AUTOSAR XML (schema 4-2-2)
package /ComponentTypes
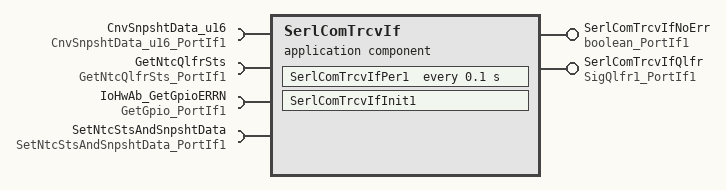
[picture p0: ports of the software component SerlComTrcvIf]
  application sw component type SerlComTrcvIf
    provide port SerlComTrcvIfNoErr: nonqueued-sender-com-spec{data-element=Logl, init-value=0}, provided-interface=boolean_PortIf1
    provide port SerlComTrcvIfQlfr: nonqueued-sender-com-spec{data-element=Val, init-value=0}, provided-interface=SigQlfr1_PortIf1
    4 x require port, all with client-com-spec=Oper:
      CnvSnpshtData_u16: required-interface=CnvSnpshtData_u16_PortIf1
      GetNtcQlfrSts: required-interface=GetNtcQlfrSts_PortIf1
      IoHwAb_GetGpioERRN: required-interface=GetGpio_PortIf1
      SetNtcStsAndSnpshtData: required-interface=SetNtcStsAndSnpshtData_PortIf1
    behavior SerlComTrcvIf_InternalBehavior
      ar-typed-per-instance-memorys:
        4 x data, all with sw-calibration-access=READ-ONLY:
          dSerlComTrcvIfStsReg: type=uint16
          SerlComTrcvIfFltErrPin: type=boolean
          SerlComTrcvIfSpiErrCntr: type=uint8
          SerlComTrcvIfSt: type=uint8
      init event SerlComTrcvIf_InitEvent: start-on-event=SerlComTrcvIfInit1
      timing event TMT_SerlComTrcvIfPer1: start-on-event=SerlComTrcvIfPer1, period=0.1
      port-api-options:
        enable-take-address=false, error-handling=NO-TRANSFORMER-ERROR-HANDLING, indirect-api=false, port=CnvSnpshtData_u16
        enable-take-address=false, error-handling=NO-TRANSFORMER-ERROR-HANDLING, indirect-api=false, port=GetNtcQlfrSts
        enable-take-address=false, error-handling=NO-TRANSFORMER-ERROR-HANDLING, indirect-api=false, port=IoHwAb_GetGpioERRN
        enable-take-address=false, error-handling=NO-TRANSFORMER-ERROR-HANDLING, indirect-api=false, port=SerlComTrcvIfNoErr
        enable-take-address=false, error-handling=NO-TRANSFORMER-ERROR-HANDLING, indirect-api=false, port=SerlComTrcvIfQlfr
        enable-take-address=false, error-handling=NO-TRANSFORMER-ERROR-HANDLING, indirect-api=false, port=SetNtcStsAndSnpshtData
      runnable SerlComTrcvIfInit1
      runnable SerlComTrcvIfPer1
        data-send-points:
          access SEND_SerlComTrcvIfNoErr_Logl: accessed-variable=SerlComTrcvIfNoErr.Logl
          access SEND_SerlComTrcvIfQlfr_Val: accessed-variable=SerlComTrcvIfQlfr.Val
        4 x sync call, all with timeout=0:
          SC_CnvSnpshtData_u16_Oper: operation=CnvSnpshtData_u16.Oper
          SC_GetNtcQlfrSts_Oper: operation=GetNtcQlfrSts.Oper
          SC_IoHwAb_GetGpioERRN_Oper: operation=IoHwAb_GetGpioERRN.Oper
          SC_SetNtcStsAndSnpshtData_Oper: operation=SetNtcStsAndSnpshtData.Oper
  swc implementation SerlComTrcvIf_Implementation: behavior=SerlComTrcvIf_InternalBehavior
    code-descriptors:
      code Default: artifact-descriptors=autosar-engineering-object={short-label=Default, category=SWSRC}
